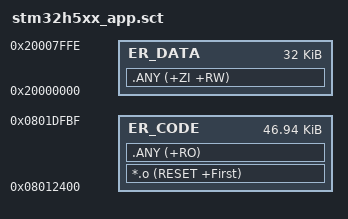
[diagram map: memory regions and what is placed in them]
#! armclang --target=arm-arm-none-eabi -march=armv8-m.main -E -xc

/*
 * Copyright (c) 2017-2018 ARM Limited
 *
 * Licensed under the Apache License, Version 2.0 (the "License");
 * you may not use this file except in compliance with the License.
 * You may obtain a copy of the License at
 *
 *     http://www.apache.org/licenses/LICENSE-2.0
 *
 * Unless required by applicable law or agreed to in writing, software
 * distributed under the License is distributed on an "AS IS" BASIS,
 * WITHOUT WARRANTIES OR CONDITIONS OF ANY KIND, either express or implied.
 * See the License for the specific language governing permissions and
 * limitations under the License.
 */

#define CODE_OFFSET 0x12000                                     /* This define is updated automatically from OEMiROT_BOOT project */
#define CODE_SIZE 0xC000                                        /* This define is updated automatically from OEMiROT_BOOT project */

#define IMAGE_HEADER_SIZE 0x400                                 /* mcuboot header size */
#define TRAILER_MAX_SIZE 0x40                                   /* Trailer max size */

#define CODE_START 0x08000000 + CODE_OFFSET + IMAGE_HEADER_SIZE
#define APP_CODE_SIZE CODE_SIZE - TRAILER_MAX_SIZE - IMAGE_HEADER_SIZE

#define DATA_START 0x20000000
#define DATA_SIZE 0x7FFF

LR_CODE CODE_START {
    ER_CODE CODE_START APP_CODE_SIZE {
        *.o (RESET +First)
        .ANY (+RO)
    }

    ER_DATA DATA_START DATA_SIZE {
        .ANY (+ZI +RW)
    }
}

